# R7KA8T2AD register map
Vendor: Renesas Electronics Corporation; Series: RA8; File version: 1.10.02
CPU: CM85 r0p2, little endian, MPU, FPU, VTOR, 4 interrupt priority bits, 96 interrupts
Registers are 32-bit, read-write, reset 0x0 unless marked. A register's access mark holds for its fields unless they carry their own. Offsets are from the block's base; [hi:lo] are bit positions; <NAME> marks a mode.

## IIC0WU — Inter-Integrated Circuit 0 Wake-up Unit
Base 0x4025E014
Same registers: IIC0WU_NS 0x5025E014
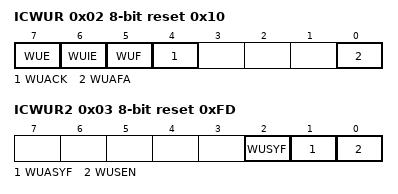
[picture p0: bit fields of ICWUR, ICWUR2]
0x02 ICWUR 8-bit reset 0x10 — I2C Bus Wakeup Unit Register
  [7] WUE — Wakeup Function Enable
    0=Disable wakeup function; 1=Enable wakeup function
  [6] WUIE — Wakeup Interrupt Request Enable
    0=Disable wakeup interrupt request (IIC0_WUI); 1=Enable wakeup interrupt request (IIC0_WUI)
  [5] WUF — Wakeup Event Occurrence Flag
    0=Slave address not matching during wakeup; 1=Slave address matching during wakeup
  [4] WUACK — ACK Bit for Wakeup Mode
  [0] WUAFA — Wakeup Analog Filter Additional Selection
    0=Do not add the wakeup analog filter; 1=Add the wakeup analog filter
0x03 ICWUR2 8-bit reset 0xFD — I2C Bus Wakeup Unit Register 2
  [2] WUSYF ro — Wakeup Function Synchronous Operation Status Flag
    0=IIC asynchronous circuit enable condition; 1=IIC synchronous circuit enable condition
  [1] WUASYF ro — Wakeup Function Asynchronous Operation Status Flag
    0=IIC synchronous circuit enable condition; 1=IIC asynchronous circuit enable condition
  [0] WUSEN — Wakeup Function Synchronous Enable
    0=IIC asynchronous circuit enable; 1=IIC synchronous circuit enable

## DOTF0
Base 0x40268800
Same registers: DOTF1 0x40268900, DOTF0_NS 0x50268800, DOTF1_NS 0x50268900
0x00 CONVAREAST — DOTF Conversion Area Start Address Register
  [31:12] CONVAREAST — The first address of the decryption processing area. The actual address is CONVAREAST[31:12] × 0x1000.
0x04 CONVAREAD — DOTF Conversion Area End Address Register
  [31:12] CONVAREAED — The end address of the decryption processing area. The actual address is CONVAREAED[31:12] ×0x1000.

## CRC — Cyclic Redundancy Check Calculator
Base 0x40310000
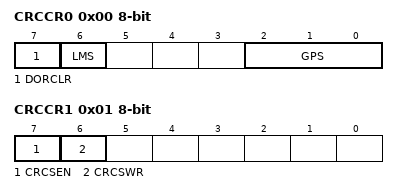
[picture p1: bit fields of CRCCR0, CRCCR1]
0x00 CRCCR0 8-bit — CRC Control Register 0
  [7] DORCLR wo — CRCDOR/CRCDOR_HA/CRCDOR_BY Register Clear
    0=No effect; 1=Clear the CRCDOR/CRCDOR_HA/CRCDOR_BY register
  [6] LMS — CRC Calculation Switching
    0=Generate CRC code for LSB-first communication; 1=Generate CRC code for MSB-first communication
  [2:0] GPS — CRC Generating Polynomial Switching
    1=8-bit CRC-8 (X8 + X2 + X + 1); 2=16-bit CRC-16 (X16 + X15 + X2 + 1); 3=16-bit CRC-CCITT (X16 + X12 + X5 + 1); 4=32-bit CRC-32 (X32 + X26 + X23 + X22 + X16 + X12 + X11 +X10 + X8 + X7 + X5 + X4 + X2 + X + 1); 5=32-bit CRC-32C (X32 + X28 + X27 + X26 + X25 + X23 + X22 + X20 + X19 + X18 + X14 + X13 + X11 + X10 + X9 + X8 + X6 + 1); other=Others (No calculation is executed)
0x01 CRCCR1 8-bit — CRC Control Register 1
  [7] CRCSEN — Snoop Enable
    0=Disabled; 1=Enabled
  [6] CRCSWR — Snoop-On-Write/Read Switch
    0=Snoop-on-read; 1=Snoop-on-write
0x04 CRCDIR — CRC Data Input Register
0x04 CRCDIR_BY 8-bit (alternate view of CRCDIR) — CRC Data Input Register
0x08 CRCDOR — CRC Data Output Register
0x08 CRCDOR_HA 16-bit (alternate view of CRCDOR) — CRC Data Output Register
0x08 CRCDOR_BY 8-bit (alternate view of CRCDOR) — CRC Data Output Register
0x0C CRCSAR 16-bit — Snoop Address Register
  [13:0] CRCSA — Register Snoop Address

## DOC_B — Data Operation Circuit
Base 0x40311000
Same registers: DOC_B_NS 0x50311000
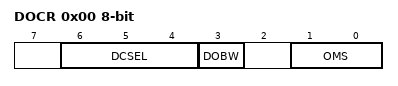
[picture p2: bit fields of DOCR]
0x00 DOCR 8-bit — DOC Control Register
  [6:4] DCSEL — Detection Condition Select
    0=Mismatch (DODSR0 ≠ DODIR); 1=Match (DODSR0 = DODIR); 2=Lower (DODSR0 > DODIR); 3=Upper (DODSR0 < DODIR); 4=Inside window (DODSR0 < DODIR < DODSR1); 5=Outside window (DODIR < DODSR0, DODSR1 < DODIR); other=Others (Setting prohibited)
  [3] DOBW — Data Operation Bit Width Select
    0=16-bit; 1=32-bit
  [1:0] OMS — Operating Mode Select
    0=Data comparison mode; 1=Data addition mode; 2=Data subtraction mode; 3=Setting prohibited
0x04 DOSR 8-bit ro — DOC Flag Status Register
  [0] DOPCF — Data Operation Circuit Flag
0x08 DOSCR 8-bit wo — DOC Flag Status Clear Register
  [0] DOPCFCL — DOPCF Clear
    0=Maintains the DOPCF flag state; 1=Clears the DOPCF flag
0x0C DODIR — DOC Data Input Register
0x10 DODSR0 — DOC Data Setting Register 0
0x14 DODSR1 — DOC Data Setting Register 1
